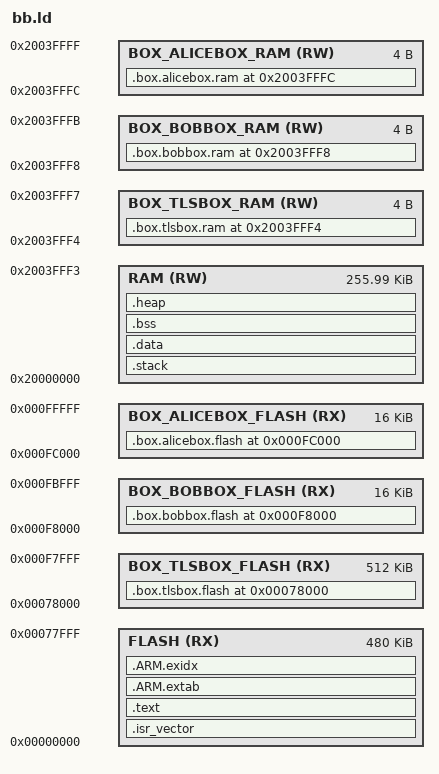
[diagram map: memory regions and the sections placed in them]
/***** AUTOGENERATED *****/

ENTRY(__box_reset_handler)

/* overridable constants */
__stack_min      = DEFINED(__stack_min) ? __stack_min : 0x00009000;
__heap_min       = DEFINED(__heap_min) ? __heap_min : 0x00032000;

MEMORY {
    FLASH            (RX ) : ORIGIN = 0x00000000, LENGTH = 0x00078000
    BOX_TLSBOX_FLASH (RX ) : ORIGIN = 0x00078000, LENGTH = 0x00080000
    BOX_BOBBOX_FLASH (RX ) : ORIGIN = 0x000f8000, LENGTH = 0x00004000
    BOX_ALICEBOX_FLASH (RX ) : ORIGIN = 0x000fc000, LENGTH = 0x00004000
    RAM              (RW ) : ORIGIN = 0x20000000, LENGTH = 0x0003fff4
    BOX_TLSBOX_RAM   (RW ) : ORIGIN = 0x2003fff4, LENGTH = 0x00000004
    BOX_BOBBOX_RAM   (RW ) : ORIGIN = 0x2003fff8, LENGTH = 0x00000004
    BOX_ALICEBOX_RAM (RW ) : ORIGIN = 0x2003fffc, LENGTH = 0x00000004
}

SECTIONS {
    /* FLASH sections */
    . = ORIGIN(FLASH);
    . = ALIGN(4);
    __isr_vector_start = .;
    .isr_vector . : {
        KEEP(*(.isr_vector))
        . = __isr_vector_start + 0x400;
    } > FLASH
    . = ALIGN(4);
    __isr_vector_end = .;

    . = ALIGN(4);
    __text_start = .;
    .text . : {
        *(.text*)
        *(.rodata*)
        *(.glue_7*)
        *(.glue_7t*)
        *(.eh_frame*)

        KEEP(*(SORT_NONE(.init)))
        KEEP(*(SORT_NONE(.init*)))
        KEEP(*(SORT_NONE(.fini)))
        KEEP(*(SORT_NONE(.fini*)))

        . = ALIGN(4);
        PROVIDE_HIDDEN(__preinit_array_start = .);
        KEEP(*(SORT(.preinit_array)))
        PROVIDE_HIDDEN(__preinit_array_end = .);

        . = ALIGN(4);
        PROVIDE_HIDDEN(__init_array_start = .);
        KEEP(*(SORT(.init_array.*)))
        PROVIDE_HIDDEN(__init_array_end = .);

        . = ALIGN(4);
        PROVIDE_HIDDEN(__fini_array_start = .);
        KEEP(*(SORT(.fini_array.*)))
        PROVIDE_HIDDEN(__fini_array_end = .);

        KEEP(*crtbegin.o(.ctors))
        KEEP(*crtbegin?.o(.ctors))
        KEEP(*(EXCLUDE_FILE(*crtend?.o *crtend.o) .ctors))
        KEEP(*(SORT(.ctors.*)))

        KEEP(*crtbegin.o(.dtors))
        KEEP(*crtbegin?.o(.dtors))
        KEEP(*(EXCLUDE_FILE(*crtend?.o *crtend.o) .dtors))
        KEEP(*(SORT(.dtors.*)))
    } > FLASH
    . = ALIGN(4);
    __text_end = .;

    __extab_start = .;
    .ARM.extab : {
        *(.ARM.extab* .gnu.linkonce.armextab.*)
    } > FLASH
    __extab_end = .;

    __exidx_start = .;
    .ARM.exidx : {
        *(.ARM.exidx* .gnu.linkonce.armexidx.*)
    } > FLASH
    __exidx_end = .;

    . = ALIGN(4);
    __data_init_start = .;

    /* BOX_TLSBOX_FLASH sections */
    . = ORIGIN(BOX_TLSBOX_FLASH);
    __box_tlsbox_flash_start = .;
    .box.tlsbox.flash . : {
        KEEP(*(.box.tlsbox.flash*))
    } > BOX_TLSBOX_FLASH
    . = ORIGIN(BOX_TLSBOX_FLASH) + LENGTH(BOX_TLSBOX_FLASH);
    __box_tlsbox_flash_end = .;

    __box_tlsbox_image = __box_tlsbox_flash_start;

    /* BOX_BOBBOX_FLASH sections */
    . = ORIGIN(BOX_BOBBOX_FLASH);
    __box_bobbox_flash_start = .;
    .box.bobbox.flash . : {
        KEEP(*(.box.bobbox.flash*))
    } > BOX_BOBBOX_FLASH
    . = ORIGIN(BOX_BOBBOX_FLASH) + LENGTH(BOX_BOBBOX_FLASH);
    __box_bobbox_flash_end = .;

    __box_bobbox_image = __box_bobbox_flash_start;

    /* BOX_ALICEBOX_FLASH sections */
    . = ORIGIN(BOX_ALICEBOX_FLASH);
    __box_alicebox_flash_start = .;
    .box.alicebox.flash . : {
        KEEP(*(.box.alicebox.flash*))
    } > BOX_ALICEBOX_FLASH
    . = ORIGIN(BOX_ALICEBOX_FLASH) + LENGTH(BOX_ALICEBOX_FLASH);
    __box_alicebox_flash_end = .;

    __box_alicebox_image = __box_alicebox_flash_start;

    /* RAM sections */
    . = ORIGIN(RAM);
    . = ALIGN(4);
    __stack_start = .;
    .stack . (NOLOAD) : {
        . = .;
    } > RAM
    . += __stack_min;
    . = ALIGN(4);
    __stack_end = .;

    . = ALIGN(4);
    __data_start = .;
    .data . : AT(__data_init_start) {
        *(.data*)
    } > RAM
    . = ALIGN(4);
    __data_end = .;

    __data_init_end = LOADADDR(.data) + SIZEOF(.data);
    ASSERT(__data_init_end <= ORIGIN(FLASH) + LENGTH(FLASH),
        "Not enough memory in FLASH for data init")

    . = ALIGN(4);
    __bss_start = .;
    __bss_start__ = .;
    .bss . (NOLOAD) : {
        *(.bss*)
        *(COMMON)
    } > RAM
    . = ALIGN(4);
    __bss_end = .;
    __bss_end__ = .;

    . = ALIGN(4);
    __heap_start = .;
    __end__ = .;
    PROVIDE(end = .);
    .heap . (NOLOAD) : {
        . = .;
    } > RAM
    . = ORIGIN(RAM) + LENGTH(RAM);
    . = ALIGN(4);
    __heap_end = .;
    __heap_limit = .;

    ASSERT(__heap_end - __heap_start > __heap_min,
        "Not enough memory in RAM for heap")

    /* BOX_TLSBOX_RAM sections */
    . = ORIGIN(BOX_TLSBOX_RAM);
    __box_tlsbox_ram_start = .;
    .box.tlsbox.ram . (NOLOAD): {
        KEEP(*(.box.tlsbox.ram*))
    } > BOX_TLSBOX_RAM
    . = ORIGIN(BOX_TLSBOX_RAM) + LENGTH(BOX_TLSBOX_RAM);
    __box_tlsbox_ram_end = .;

    /* BOX_BOBBOX_RAM sections */
    . = ORIGIN(BOX_BOBBOX_RAM);
    __box_bobbox_ram_start = .;
    .box.bobbox.ram . (NOLOAD): {
        KEEP(*(.box.bobbox.ram*))
    } > BOX_BOBBOX_RAM
    . = ORIGIN(BOX_BOBBOX_RAM) + LENGTH(BOX_BOBBOX_RAM);
    __box_bobbox_ram_end = .;

    /* BOX_ALICEBOX_RAM sections */
    . = ORIGIN(BOX_ALICEBOX_RAM);
    __box_alicebox_ram_start = .;
    .box.alicebox.ram . (NOLOAD): {
        KEEP(*(.box.alicebox.ram*))
    } > BOX_ALICEBOX_RAM
    . = ORIGIN(BOX_ALICEBOX_RAM) + LENGTH(BOX_ALICEBOX_RAM);
    __box_alicebox_ram_end = .;
}

